# ATSAMA5D27 register map
Vendor: Microchip Technology Inc.; File version: 1.0
CPU: CA5 r0p1, little endian, no MPU, no FPU, 4 interrupt priority bits
Address unit: 32 bits
Registers are 32-bit, read-write, reset 0x0 unless marked. A register's access mark holds for its fields unless they carry their own. Offsets are from the block's base; [hi:lo] are bit positions; {n}, {i} and the like mark numbered series.

## SMC — Static Memory Controller
Base 0xF8014000
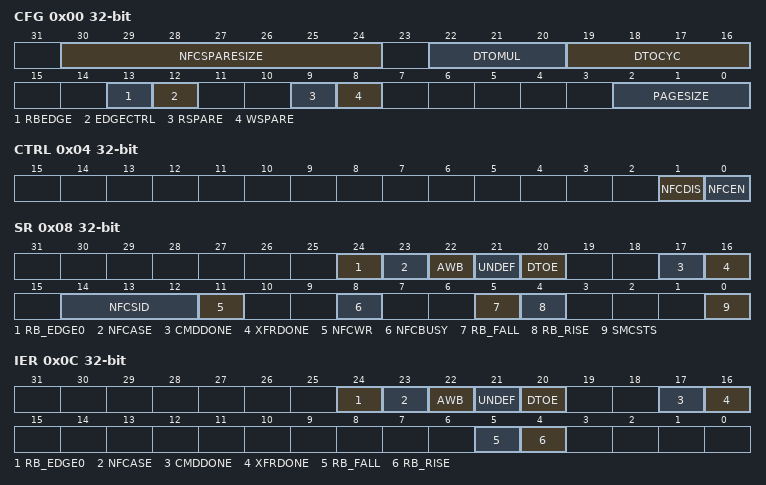
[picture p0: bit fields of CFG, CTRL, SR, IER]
0x00 CFG — NFC Configuration Register
  [30:24] NFCSPARESIZE — NAND Flash Spare Area Size Retrieved by the Host Controller
  [22:20] DTOMUL — Data Timeout Multiplier
    0=DTOCYC; 1=X16 (DTOCYC x 16); 2=X128 (DTOCYC x 128); 3=X256 (DTOCYC x 256); 4=X1024 (DTOCYC x 1024); 5=X4096 (DTOCYC x 4096); 6=X65536 (DTOCYC x 65536); 7=X1048576 (DTOCYC x 1048576)
  [19:16] DTOCYC — Data Timeout Cycle Number
  [13] RBEDGE — Ready/Busy Signal Edge Detection
  [12] EDGECTRL — Rising/Falling Edge Detection Control
  [9] RSPARE — Read Spare Area
  [8] WSPARE — Write Spare Area
  [2:0] PAGESIZE — Page Size of the NAND Flash Device
    0=PS512 (Main area 512 bytes); 1=PS1024 (Main area 1024 bytes); 2=PS2048 (Main area 2048 bytes); 3=PS4096 (Main area 4096 bytes); 4=PS8192 (Main area 8192 bytes)
0x04 CTRL wo — NFC Control Register
  [1] NFCDIS rw — NAND Flash Controller Disable
  [0] NFCEN rw — NAND Flash Controller Enable
0x08 SR ro — NFC Status Register
  [24] RB_EDGE0 rw — Ready/Busy Line 0 Edge Detected
  [23] NFCASE rw — NFC Access Size Error
  [22] AWB rw — Accessing While Busy
  [21] UNDEF rw — Undefined Area Error
  [20] DTOE rw — Data Timeout Error
  [17] CMDDONE rw — Command Done
  [16] XFRDONE rw — NFC Data Transfer Terminated
  [14:12] NFCSID rw — NFC Chip Select ID (this field cannot be reset)
  [11] NFCWR rw — NFC Write/Read Operation (this field cannot be reset)
  [8] NFCBUSY rw — NFC Busy (this field cannot be reset)
  [5] RB_FALL rw — Selected Ready Busy Falling Edge Detected
  [4] RB_RISE rw — Selected Ready Busy Rising Edge Detected
  [0] SMCSTS rw — NAND Flash Controller Status (this field cannot be reset)
0x0C IER wo — NFC Interrupt Enable Register
  [24] RB_EDGE0 rw — Ready/Busy Line 0 Interrupt Enable
  [23] NFCASE rw — NFC Access Size Error Interrupt Enable
  [22] AWB rw — Accessing While Busy Interrupt Enable
  [21] UNDEF rw — Undefined Area Access Interrupt Enable
  [20] DTOE rw — Data Timeout Error Interrupt Enable
  [17] CMDDONE rw — Command Done Interrupt Enable
  [16] XFRDONE rw — Transfer Done Interrupt Enable
  [5] RB_FALL rw — Ready Busy Falling Edge Detection Interrupt Enable
  [4] RB_RISE rw — Ready Busy Rising Edge Detection Interrupt Enable
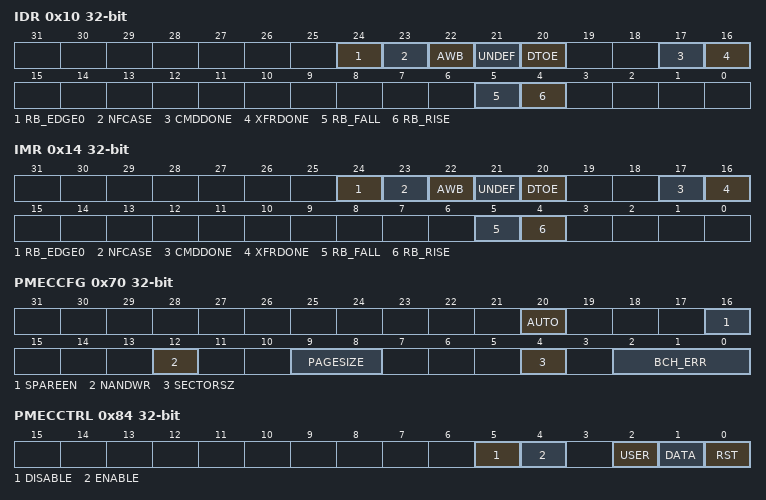
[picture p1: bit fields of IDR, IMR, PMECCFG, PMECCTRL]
0x10 IDR wo — NFC Interrupt Disable Register
  [24] RB_EDGE0 rw — Ready/Busy Line 0 Interrupt Disable
  [23] NFCASE rw — NFC Access Size Error Interrupt Disable
  [22] AWB rw — Accessing While Busy Interrupt Disable
  [21] UNDEF rw — Undefined Area Access Interrupt Disable
  [20] DTOE rw — Data Timeout Error Interrupt Disable
  [17] CMDDONE rw — Command Done Interrupt Disable
  [16] XFRDONE rw — Transfer Done Interrupt Disable
  [5] RB_FALL rw — Ready Busy Falling Edge Detection Interrupt Disable
  [4] RB_RISE rw — Ready Busy Rising Edge Detection Interrupt Disable
0x14 IMR ro — NFC Interrupt Mask Register
  [24] RB_EDGE0 rw — Ready/Busy Line 0 Interrupt Mask
  [23] NFCASE rw — NFC Access Size Error Interrupt Mask
  [22] AWB rw — Accessing While Busy Interrupt Mask
  [21] UNDEF rw — Undefined Area Access Interrupt Mask5
  [20] DTOE rw — Data Timeout Error Interrupt Mask
  [17] CMDDONE rw — Command Done Interrupt Mask
  [16] XFRDONE rw — Transfer Done Interrupt Mask
  [5] RB_FALL rw — Ready Busy Falling Edge Detection Interrupt Mask
  [4] RB_RISE rw — Ready Busy Rising Edge Detection Interrupt Mask
0x18 ADDR — NFC Address Cycle Zero Register
  [7:0] ADDR_CYCLE0 — NAND Flash Array Address Cycle 0
0x1C BANK — Bank Address Register
  [0] BANK — Bank Identifier
0x70 PMECCFG — PMECC Configuration Register
  [20] AUTO — Automatic Mode Enable
  [16] SPAREEN — Spare Enable
  [12] NANDWR — NAND Write Access
  [9:8] PAGESIZE — Number of Sectors in the Page
    0=PAGESIZE_1SEC (1 sector for main area (512 or 1024 bytes)); 1=PAGESIZE_2SEC (2 sectors for main area (1024 or 2048 bytes)); 2=PAGESIZE_4SEC (4 sectors for main area (2048 or 4096 bytes)); 3=PAGESIZE_8SEC (8 sectors for main area (4096 or 8192 bytes))
  [4] SECTORSZ — Sector Size
    0=Use 512 Byte Sector in ECC Computation; 1=Use 1024 Byte Sector in ECC Computation
  [2:0] BCH_ERR — Error Correcting Capability
    0=2 errors; 1=4 errors; 2=8 errors; 3=12 errors; 4=24 errors; 5=32 errors
0x74 PMECCSAREA — PMECC Spare Area Size Register
  [8:0] SPARESIZE — Spare Area Size
0x78 PMECCSADDR — PMECC Start Address Register
  [8:0] STARTADDR — ECC Area Start Address
0x7C PMECCEADDR — PMECC End Address Register
  [8:0] ENDADDR — ECC Area End Address
0x84 PMECCTRL wo — PMECC Control Register
  [5] DISABLE rw — PMECC Enable
  [4] ENABLE rw — PMECC Enable
  [2] USER rw — Start a User Mode Phase
  [1] DATA rw — Start a Data Phase
  [0] RST rw — Reset the PMECC Module
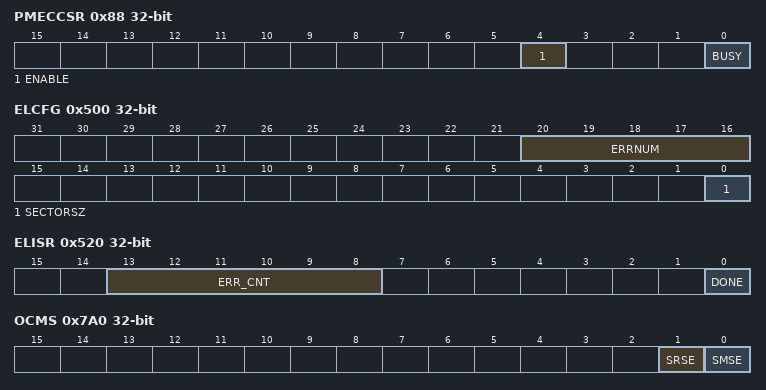
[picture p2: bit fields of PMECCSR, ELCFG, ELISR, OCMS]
0x88 PMECCSR ro — PMECC Status Register
  [4] ENABLE rw — PMECC Enable bit
  [0] BUSY rw — The kernel of the PMECC is busy
0x8C PMECCIER wo — PMECC Interrupt Enable register
  [0] ERRIE rw — Error Interrupt Enable
0x90 PMECCIDR wo — PMECC Interrupt Disable Register
  [0] ERRID rw — Error Interrupt Disable
0x94 PMECCIMR ro — PMECC Interrupt Mask Register
  [0] ERRIM rw — Error Interrupt Mask
0x98 PMECCISR ro — PMECC Interrupt Status Register
  [7:0] ERRIS rw — Error Interrupt Status Register
0x500 ELCFG — PMECC Error Location Configuration Register
  [20:16] ERRNUM — Number of Errors
  [0] SECTORSZ — Sector Size
    0=Use 512 Byte Sector in Location Computation; 1=Use 1024 Byte Sector in Location Computation
0x504 ELPRIM ro — PMECC Error Location Primitive Register
  [15:0] PRIMITIV rw — Primitive Polynomial
0x508 ELEN wo — PMECC Error Location Enable Register
  [13:0] ENINIT rw — Error Location Enable
0x50C ELDIS wo — PMECC Error Location Disable Register
  [0] DIS rw — Disable Error Location Engine
0x510 ELSR ro — PMECC Error Location Status Register
  [0] BUSY rw — Error Location Engine Busy
0x514 ELIER wo — PMECC Error Location Interrupt Enable register
  [0] DONE rw — Computation Terminated Interrupt Enable
0x518 ELIDR wo — PMECC Error Location Interrupt Disable Register
  [0] DONE rw — Computation Terminated Interrupt Disable
0x51C ELIMR ro — PMECC Error Location Interrupt Mask Register
  [0] DONE rw — Computation Terminated Interrupt Mask
0x520 ELISR ro — PMECC Error Location Interrupt Status Register
  [13:8] ERR_CNT rw — Error Counter value
  [0] DONE rw — Computation Terminated Interrupt Status
0x528 SIGMA0 ro — PMECC Error Location SIGMA 0 Register
  [13:0] SIGMA0 rw — Coefficient of degree 0 in the SIGMA polynomial
{0x528+4i} SIGMA{i} (i=1..32) — PMECC Error Location SIGMA {i} Register
  [13:0] SIGMA{i} — Coefficient of degree x in the SIGMA polynomial
0x5AC ERRLOC ro — PMECC Error Location 0 Register
  [13:0] ERRLOCN rw — Error Position within the Set {sector area, spare area}
0x7A0 OCMS — Off Chip Memory Scrambling Register
  [1] SRSE — NFC Internal SRAM Scrambling Enable
  [0] SMSE — Static Memory Controller Scrambling Enable
0x7A4 KEY1 wo — Off Chip Memory Scrambling KEY1 Register
  [31:0] KEY1 rw — Off Chip Memory Scrambling (OCMS) Key Part 1
0x7A8 KEY2 wo — Off Chip Memory Scrambling KEY2 Register
  [31:0] KEY2 rw — Off Chip Memory Scrambling (OCMS) Key Part 2
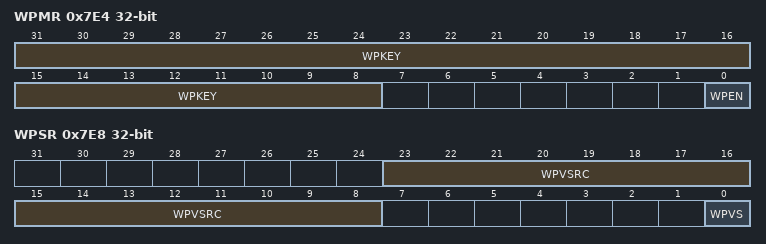
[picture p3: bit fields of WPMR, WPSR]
0x7E4 WPMR — Write Protection Mode Register
  [31:8] WPKEY — Write Protection Key
    0x534D43=PASSWD (Writing any other value in this field aborts the write operation of bit WPEN.Always reads as 0.)
  [0] WPEN — Write Protection Enable
0x7E8 WPSR ro — Write Protection Status Register
  [23:8] WPVSRC rw — Write Protection Violation Source
  [0] WPVS rw — Write Protection Violation Status
